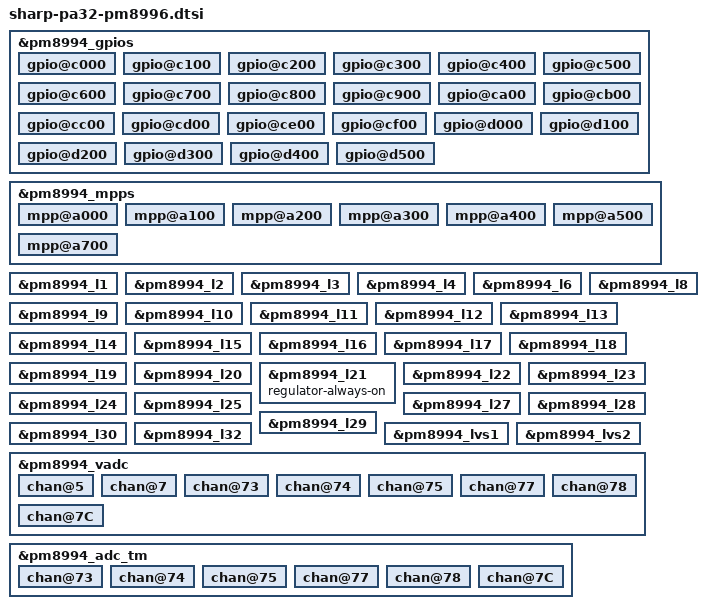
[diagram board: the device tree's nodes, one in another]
/* Copyright (c) 2015, The Linux Foundation. All rights reserved.
 *
 * This program is free software; you can redistribute it and/or modify
 * it under the terms of the GNU General Public License version 2 and
 * only version 2 as published by the Free Software Foundation.
 *
 * This program is distributed in the hope that it will be useful,
 * but WITHOUT ANY WARRANTY; without even the implied warranty of
 * MERCHANTABILITY or FITNESS FOR A PARTICULAR PURPOSE.  See the
 * GNU General Public License for more details.
 */

/*****************************************/

/*****************************************/
/*  pm8994-gpios: qpnp-pin               */
/*****************************************/

&pm8994_gpios {

	gpio@c000 { /* GPIO_01 */
	};

	gpio@c100 { /* GPIO_02 */
	};

	gpio@c200 { /* GPIO_03 */
	};

	gpio@c300 { /* GPIO_04 */
	};

	gpio@c400 { /* GPIO_05 */
	};

	gpio@c500 { /* GPIO_06 */
	};

	gpio@c600 { /* GPIO_07 */
	};

	gpio@c700 { /* GPIO_08 */
	};

	gpio@c800 { /* GPIO_09 */
	};

	gpio@c900 { /* GPIO_10 */
	};

	gpio@ca00 { /* GPIO_11 */
	};

	gpio@cb00 { /* GPIO_12 */
	};

	gpio@cc00 { /* GPIO_13 */
	};

	gpio@cd00 { /* GPIO_14 */
	};

	gpio@ce00 { /* GPIO_15 */
	};

	gpio@cf00 { /* GPIO_16 */
	};

	gpio@d000 { /* GPIO_17 */
	};

	gpio@d100 { /* GPIO_18 */
	};

	gpio@d200 { /* GPIO_19 */
	};

	gpio@d300 { /* GPIO_20 */
	};

	gpio@d400 { /* GPIO_21 */
	};

	gpio@d500 { /* GPIO_22 */
	};
};

/*****************************************/
/*  pm8994-mpps: qpnp-pin                */
/*****************************************/

&pm8994_mpps {

	mpp@a000 { /* MPP_01 */
	};

	mpp@a100 { /* MPP_02 */
	};

	mpp@a200 { /* MPP_03 */
	};

	mpp@a300 { /* MPP_04 */
	};

	mpp@a400 { /* MPP_05 */
	};

	mpp@a500 { /* MPP_06 */
	};

//	mpp@a600 { /* MPP_07 */
//	};
//
	mpp@a700 { /* MPP_08 */
	};
};
/*****************************************/
/*  pm8994: rpm-regulator                */
/*****************************************/
&pm8994_l1 { /* 8994_l1 */
};

&pm8994_l2 { /* 8994_l2 */
};

&pm8994_l3 { /* 8994_l3 */
};

&pm8994_l4 { /* 8994_l4 */
};

//&pm8994_l5 { /* 8994_l5 not found*/
//};

&pm8994_l6 { /* 8994_l6 */
};

//&pm8994_l7 { /* 8994_l7 not found*/
//};

&pm8994_l8 { /* 8994_l8 */
};

&pm8994_l9 { /* 8994_l9 */
};

&pm8994_l10 { /* 8994_l10 */
};

&pm8994_l11 { /* 8994_l11 */
};

&pm8994_l12 { /* 8994_l12 */
};

&pm8994_l13 { /* 8994_l13 */
};

&pm8994_l14 { /* 8994_l14 */
};

&pm8994_l15 { /* 8994_l15 */
};

&pm8994_l16 { /* 8994_l16 */
};

&pm8994_l17 { /* 8994_l17 */
};

&pm8994_l18 { /* 8994_l18 */
};

&pm8994_l19 { /* 8994_l19 */
};

&pm8994_l20 { /* 8994_l20 */
};

&pm8994_l21 { /* 8994_l21 */
	regulator-always-on;
};

&pm8994_l22 { /* 8994_l22 */
};

&pm8994_l23 { /* 8994_l23 */
};

&pm8994_l24 { /* 8994_l24 */
};

&pm8994_l25 { /* 8994_l25 */
};

//&pm8994_l26 { /* 8994_l26 */
//};

&pm8994_l27 { /* 8994_l27 */
};

&pm8994_l28 { /* 8994_l28 */
};

&pm8994_l29 { /* 8994_l29 */
};

&pm8994_l30 { /* 8994_l30 */
};

//&pm8994_l31 { /* 8994_l31 */
//};

&pm8994_l32 { /* 8994_l32 */
};

&pm8994_lvs1 { /* 8994_lvs1 */
};

&pm8994_lvs2 { /* 8994_lvs2 */
};

/*****************************************/
/*  qpnp-adc-voltage                     */
/*****************************************/

&pm8994_vadc {
	chan@5 {
	};

	chan@7 {
	};

	chan@73 { /* msm_therm */
	};

	chan@74 { /* emmc_therm -> cam_therm */
	};

	chan@75 { /* pa_therm0 */
	};

	chan@77 { /* pa_therm1 */
	};

	chan@78 { /* quiet_therm -> lcd_therm */
	};

	chan@7C { /* xo_therm */
	};
};


/*****************************************/
/*  qpnp-vadc-tm                         */
/*****************************************/

&pm8994_adc_tm {
	chan@73 { /* msm_therm */
	};

	chan@74 { /* emmc_therm -> cam_therm */
	};

	chan@75 { /* pa_therm0 */
	};

	chan@77 { /* pa_therm1 */
	};

	chan@78 { /* quiet_therm -> lcd_therm */
	};

	chan@7C { /* xo_therm */
	};
};
